AUTOSAR XML (schema 00051)
standard types defined: uint16, uint32
package /Components
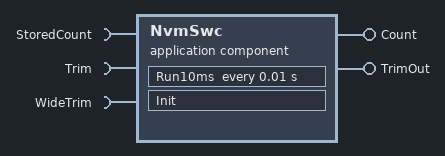
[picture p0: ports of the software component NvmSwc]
  application sw component type NvmSwc
    require port StoredCount: nonqueued-receiver-com-spec{data-element=StoredCount, init-value=0}, required-interface=StoredCount
    provide port Count: nonqueued-sender-com-spec{data-element=Count, init-value=0}, provided-interface=Count
    require port Trim: nonqueued-receiver-com-spec{data-element=Trim, init-value=500}, required-interface=Trim
    provide port TrimOut: nonqueued-sender-com-spec{data-element=TrimOut, init-value=500}, provided-interface=TrimOut
    require port WideTrim: nonqueued-receiver-com-spec{data-element=WideTrim, init-value=0}, required-interface=WideTrim
    behavior NvmSwc_IB
      init event Event_Init: start-on-event=Init
      timing event Event_Run10ms: start-on-event=Run10ms, period=0.01
      runnable Init: symbol=NvmSwc_Init
      runnable Run10ms: symbol=NvmSwc_Run10ms
package /Interfaces
  5 x sender receiver interface:
    StoredCount
      data StoredCount: type=uint32
    Count
      data Count: type=uint32
    Trim
      data Trim: type=uint16
    TrimOut
      data TrimOut: type=uint16
    WideTrim
      data WideTrim: type=uint32
